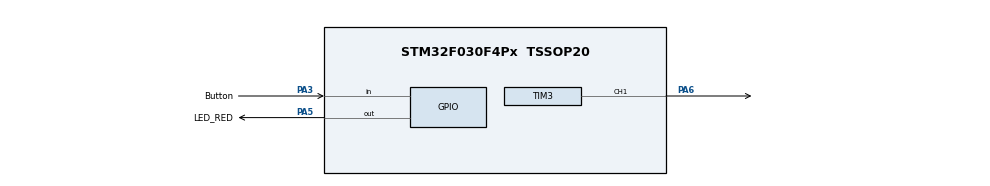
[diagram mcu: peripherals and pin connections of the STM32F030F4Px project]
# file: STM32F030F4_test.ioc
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Mcu.Family=STM32F0
Mcu.Name=STM32F030F4Px
Mcu.Package=TSSOP20
PA13.Mode=Serial_Wire
PA13.Signal=SYS_SWDIO
PA14.Mode=Serial_Wire
PA14.Signal=SYS_SWCLK
PA3.GPIO_Label=Button
PA3.GPIO_PuPd=GPIO_PULLUP
PA3.Signal=GPIO_Input
PA5.GPIO_Label=LED_RED
PA5.Signal=GPIO_Output
PA6.Signal=S_TIM3_CH1
ProjectManager.HeapSize=0x200
ProjectManager.StackSize=0x400
ProjectManager.TargetToolchain=STM32CubeIDE
SH.S_TIM3_CH1.0=TIM3_CH1,PWM Generation1 CH1
TIM3.Channel-PWM\ Generation1\ CH1=TIM_CHANNEL_1
VP_TIM14_VS_ClockSourceINT.Mode=Enable_Timer
VP_TIM3_VS_ClockSourceINT.Mode=Internal
board=custom

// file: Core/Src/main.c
/* USER CODE BEGIN Header */
/**
  ******************************************************************************
  * @file           : main.c
  * @brief          : Main program body
  ******************************************************************************
  * @attention
  *
  * Copyright (c) 2023 STMicroelectronics.
  * All rights reserved.
  *
  * This software is licensed under terms that can be found in the LICENSE file
  * in the root directory of this software component.
  * If no LICENSE file comes with this software, it is provided AS-IS.
  *
  ******************************************************************************
  */
/* USER CODE END Header */
#include "main.h"

TIM_HandleTypeDef htim3;
TIM_HandleTypeDef htim14;

void SystemClock_Config(void);
static void MX_GPIO_Init(void);
static void MX_TIM3_Init(void);
static void MX_TIM14_Init(void);

int main(void)
{

  /* MCU Configuration--------------------------------------------------------*/

  /* Reset of all peripherals, Initializes the Flash interface and the Systick. */
  HAL_Init();

  /* Configure the system clock */
  SystemClock_Config();

  /* Initialize all configured peripherals */
  MX_GPIO_Init();
  MX_TIM3_Init();
  MX_TIM14_Init();

  /* Infinite loop */
  /* USER CODE BEGIN WHILE */
  while (1)
  {
	  if(!HAL_GPIO_ReadPin(Button_GPIO_Port, Button_Pin)){

		  while(HAL_GPIO_ReadPin(Button_GPIO_Port, Button_Pin)){
			  HAL_GPIO_TogglePin(LED_GREEN_GPIO_Port, LED_GREEN_Pin);
			  HAL_Delay(600);
		  }

	  }else{
		  while(HAL_GPIO_ReadPin(Button_GPIO_Port, Button_Pin)){
		 			  HAL_GPIO_TogglePin(LED_RED_GPIO_Port, LED_RED_Pin);
		 			  HAL_Delay(600);
	  }
	 }

//	 if(!HAL_GPIO_ReadPin(Button_GPIO_Port, Button_Pin))
//	 {
//			HAL_GPIO_WritePin(LED_RED_GPIO_Port, LED_RED_Pin,GPIO_PIN_SET);
//			HAL_GPIO_WritePin(LED_GREEN_GPIO_Port, LED_GREEN_Pin,GPIO_PIN_RESET);
//
//		HAL_Delay(500);
//		 }
//	 else{
//		    HAL_GPIO_WritePin(LED_RED_GPIO_Port, LED_RED_Pin,GPIO_PIN_RESET);
//		 	HAL_GPIO_WritePin(LED_GREEN_GPIO_Port, LED_GREEN_Pin,GPIO_PIN_SET);
//		 	HAL_Delay(500);
//	 }

    /* USER CODE END WHILE */

  }
}

void SystemClock_Config(void)
{
  RCC_OscInitTypeDef RCC_OscInitStruct = {0};
  RCC_ClkInitTypeDef RCC_ClkInitStruct = {0};

  /** Initializes the RCC Oscillators according to the specified parameters
  * in the RCC_OscInitTypeDef structure.
  */
  RCC_OscInitStruct.OscillatorType = RCC_OSCILLATORTYPE_HSI;
  RCC_OscInitStruct.HSIState = RCC_HSI_ON;
  RCC_OscInitStruct.HSICalibrationValue = RCC_HSICALIBRATION_DEFAULT;
  RCC_OscInitStruct.PLL.PLLState = RCC_PLL_NONE;
  if (HAL_RCC_OscConfig(&RCC_OscInitStruct) != HAL_OK)
  {
    Error_Handler();
  }

  /** Initializes the CPU, AHB and APB buses clocks
  */
  RCC_ClkInitStruct.ClockType = RCC_CLOCKTYPE_HCLK|RCC_CLOCKTYPE_SYSCLK
                              |RCC_CLOCKTYPE_PCLK1;
  RCC_ClkInitStruct.SYSCLKSource = RCC_SYSCLKSOURCE_HSI;
  RCC_ClkInitStruct.AHBCLKDivider = RCC_SYSCLK_DIV1;
  RCC_ClkInitStruct.APB1CLKDivider = RCC_HCLK_DIV1;

  if (HAL_RCC_ClockConfig(&RCC_ClkInitStruct, FLASH_LATENCY_0) != HAL_OK)
  {
    Error_Handler();
  }
}

static void MX_TIM3_Init(void)
{

  TIM_ClockConfigTypeDef sClockSourceConfig = {0};
  TIM_MasterConfigTypeDef sMasterConfig = {0};
  TIM_OC_InitTypeDef sConfigOC = {0};

  htim3.Instance = TIM3;
  htim3.Init.Prescaler = 0;
  htim3.Init.CounterMode = TIM_COUNTERMODE_UP;
  htim3.Init.Period = 65535;
  htim3.Init.ClockDivision = TIM_CLOCKDIVISION_DIV1;
  htim3.Init.AutoReloadPreload = TIM_AUTORELOAD_PRELOAD_DISABLE;
  if (HAL_TIM_Base_Init(&htim3) != HAL_OK)
  {
    Error_Handler();
  }
  sClockSourceConfig.ClockSource = TIM_CLOCKSOURCE_INTERNAL;
  if (HAL_TIM_ConfigClockSource(&htim3, &sClockSourceConfig) != HAL_OK)
  {
    Error_Handler();
  }
  if (HAL_TIM_PWM_Init(&htim3) != HAL_OK)
  {
    Error_Handler();
  }
  sMasterConfig.MasterOutputTrigger = TIM_TRGO_RESET;
  sMasterConfig.MasterSlaveMode = TIM_MASTERSLAVEMODE_DISABLE;
  if (HAL_TIMEx_MasterConfigSynchronization(&htim3, &sMasterConfig) != HAL_OK)
  {
    Error_Handler();
  }
  sConfigOC.OCMode = TIM_OCMODE_PWM1;
  sConfigOC.Pulse = 0;
  sConfigOC.OCPolarity = TIM_OCPOLARITY_HIGH;
  sConfigOC.OCFastMode = TIM_OCFAST_DISABLE;
  if (HAL_TIM_PWM_ConfigChannel(&htim3, &sConfigOC, TIM_CHANNEL_1) != HAL_OK)
  {
    Error_Handler();
  }
  HAL_TIM_MspPostInit(&htim3);

}

static void MX_TIM14_Init(void)
{

  htim14.Instance = TIM14;
  htim14.Init.Prescaler = 0;
  htim14.Init.CounterMode = TIM_COUNTERMODE_UP;
  htim14.Init.Period = 65535;
  htim14.Init.ClockDivision = TIM_CLOCKDIVISION_DIV1;
  htim14.Init.AutoReloadPreload = TIM_AUTORELOAD_PRELOAD_DISABLE;
  if (HAL_TIM_Base_Init(&htim14) != HAL_OK)
  {
    Error_Handler();
  }

}

static void MX_GPIO_Init(void)
{
  GPIO_InitTypeDef GPIO_InitStruct = {0};

  /* GPIO Ports Clock Enable */
  __HAL_RCC_GPIOA_CLK_ENABLE();

  /*Configure GPIO pin Output Level */
  HAL_GPIO_WritePin(LED_RED_GPIO_Port, LED_RED_Pin, GPIO_PIN_RESET);

  /*Configure GPIO pin : Button_Pin */
  GPIO_InitStruct.Pin = Button_Pin;
  GPIO_InitStruct.Mode = GPIO_MODE_INPUT;
  GPIO_InitStruct.Pull = GPIO_PULLUP;
  HAL_GPIO_Init(Button_GPIO_Port, &GPIO_InitStruct);

  /*Configure GPIO pin : LED_RED_Pin */
  GPIO_InitStruct.Pin = LED_RED_Pin;
  GPIO_InitStruct.Mode = GPIO_MODE_OUTPUT_PP;
  GPIO_InitStruct.Pull = GPIO_NOPULL;
  GPIO_InitStruct.Speed = GPIO_SPEED_FREQ_LOW;
  HAL_GPIO_Init(LED_RED_GPIO_Port, &GPIO_InitStruct);

}

void Error_Handler(void)
{
  __disable_irq();
  while (1)
  {
  }
}
